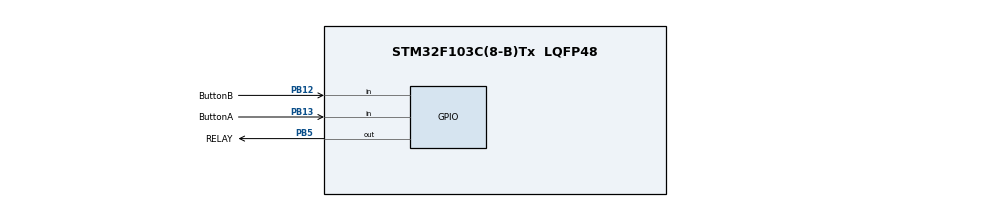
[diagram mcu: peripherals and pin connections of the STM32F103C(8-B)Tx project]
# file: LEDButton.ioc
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Mcu.Family=STM32F1
Mcu.Name=STM32F103C(8-B)Tx
Mcu.Package=LQFP48
NVIC.PriorityGroup=NVIC_PRIORITYGROUP_4
PB12.GPIO_Label=ButtonB
PB12.GPIO_PuPd=GPIO_NOPULL
PB12.Signal=GPIO_Input
PB13.GPIO_Label=ButtonA
PB13.GPIO_PuPd=GPIO_PULLUP
PB13.Signal=GPIO_Input
PB5.GPIO_Label=RELAY
PB5.GPIO_ModeDefaultOutputPP=GPIO_MODE_OUTPUT_PP
PB5.GPIO_PuPd=GPIO_NOPULL
PB5.Signal=GPIO_Output
ProjectManager.HeapSize=0x200
ProjectManager.StackSize=0x400
ProjectManager.TargetToolchain=STM32CubeIDE
RCC.APB1Freq_Value=8000000
RCC.APB2Freq_Value=8000000
board=custom

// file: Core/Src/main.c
/* USER CODE BEGIN Header */
/**
 ******************************************************************************
 * @file           : main.c
 * @brief          : Main program body
 ******************************************************************************
 * @attention
 *
 * Copyright (c) 2025 STMicroelectronics.
 * All rights reserved.
 *
 * This software is licensed under terms that can be found in the LICENSE file
 * in the root directory of this software component.
 * If no LICENSE file comes with this software, it is provided AS-IS.
 *
 ******************************************************************************
 */
/* USER CODE END Header */
#include "main.h"

/* USER CODE BEGIN PV */
int mode = 0;
/* USER CODE END PV */

void SystemClock_Config(void);
static void MX_GPIO_Init(void);
/* USER CODE BEGIN PFP */
GPIO_PinState deBouncing(GPIO_TypeDef *GPIOx, uint16_t GPIO_Pin);

/* USER CODE END PFP */

/* USER CODE BEGIN 0 */
GPIO_PinState deBouncing(GPIO_TypeDef *GPIOx, uint16_t GPIO_Pin) {
	GPIO_PinState bitstatus;
	if (HAL_GPIO_ReadPin(GPIOx, GPIO_Pin) == GPIO_PIN_SET) {
		int count = 0;
		for (int i = 0; i < 100; i++) {
			if (HAL_GPIO_ReadPin(GPIOx, GPIO_Pin) == GPIO_PIN_SET)
				count++;
		}
		if (count >= 90) {
			return GPIO_PIN_SET;
		} else {
			return GPIO_PIN_RESET;
		}
	} else {
		int count = 0;
		for (int i = 0; i < 100; i++) {
			if (HAL_GPIO_ReadPin(GPIOx, GPIO_Pin) == GPIO_PIN_RESET)
				count++;
		}
		if (count >= 90) {
			return GPIO_PIN_RESET;
		} else {
			return GPIO_PIN_SET;
		}
	}
}
/* USER CODE END 0 */

int main(void) {

	/* MCU Configuration--------------------------------------------------------*/

	/* Reset of all peripherals, Initializes the Flash interface and the Systick. */
	HAL_Init();

	/* Configure the system clock */
	SystemClock_Config();

	/* Initialize all configured peripherals */
	MX_GPIO_Init();

	/* Infinite loop */
	/* USER CODE BEGIN WHILE */
	while (1) {
		if (mode == 0) {
			if (deBouncing(ButtonA_GPIO_Port, ButtonA_Pin) == GPIO_PIN_RESET) {
				HAL_GPIO_TogglePin(RELAY_GPIO_Port, RELAY_Pin);
				while (deBouncing(ButtonA_GPIO_Port, ButtonA_Pin)
						== GPIO_PIN_RESET)
					;
			} else {

			}
			if (deBouncing(ButtonB_GPIO_Port, ButtonB_Pin) == GPIO_PIN_RESET) {
				mode = 1;
				while (deBouncing(ButtonB_GPIO_Port, ButtonB_Pin)
						== GPIO_PIN_RESET)
					;
			}
		} else if (mode == 1) {
			if (deBouncing(ButtonA_GPIO_Port, ButtonA_Pin) == GPIO_PIN_RESET) {
				HAL_GPIO_WritePin(RELAY_GPIO_Port, RELAY_Pin, GPIO_PIN_SET);

			} else {
				HAL_GPIO_WritePin(RELAY_GPIO_Port, RELAY_Pin, GPIO_PIN_RESET);
			}
			if (deBouncing(ButtonB_GPIO_Port, ButtonB_Pin) == GPIO_PIN_RESET) {
				mode = 0;
				while (deBouncing(ButtonB_GPIO_Port, ButtonB_Pin)
						== GPIO_PIN_RESET)
					;
			}
		}
		/* USER CODE END WHILE */

	}
}

void SystemClock_Config(void) {
	RCC_OscInitTypeDef RCC_OscInitStruct = { 0 };
	RCC_ClkInitTypeDef RCC_ClkInitStruct = { 0 };

	/** Initializes the RCC Oscillators according to the specified parameters
	 * in the RCC_OscInitTypeDef structure.
	 */
	RCC_OscInitStruct.OscillatorType = RCC_OSCILLATORTYPE_HSI;
	RCC_OscInitStruct.HSIState = RCC_HSI_ON;
	RCC_OscInitStruct.HSICalibrationValue = RCC_HSICALIBRATION_DEFAULT;
	RCC_OscInitStruct.PLL.PLLState = RCC_PLL_NONE;
	if (HAL_RCC_OscConfig(&RCC_OscInitStruct) != HAL_OK) {
		Error_Handler();
	}

	/** Initializes the CPU, AHB and APB buses clocks
	 */
	RCC_ClkInitStruct.ClockType = RCC_CLOCKTYPE_HCLK | RCC_CLOCKTYPE_SYSCLK
			| RCC_CLOCKTYPE_PCLK1 | RCC_CLOCKTYPE_PCLK2;
	RCC_ClkInitStruct.SYSCLKSource = RCC_SYSCLKSOURCE_HSI;
	RCC_ClkInitStruct.AHBCLKDivider = RCC_SYSCLK_DIV1;
	RCC_ClkInitStruct.APB1CLKDivider = RCC_HCLK_DIV1;
	RCC_ClkInitStruct.APB2CLKDivider = RCC_HCLK_DIV1;

	if (HAL_RCC_ClockConfig(&RCC_ClkInitStruct, FLASH_LATENCY_0) != HAL_OK) {
		Error_Handler();
	}
}

static void MX_GPIO_Init(void) {
	GPIO_InitTypeDef GPIO_InitStruct = { 0 };

	/* GPIO Ports Clock Enable */
	__HAL_RCC_GPIOB_CLK_ENABLE();

	/*Configure GPIO pin Output Level */
	HAL_GPIO_WritePin(RELAY_GPIO_Port, RELAY_Pin, GPIO_PIN_RESET);

	/*Configure GPIO pin : ButtonB_Pin */
	GPIO_InitStruct.Pin = ButtonB_Pin;
	GPIO_InitStruct.Mode = GPIO_MODE_INPUT;
	GPIO_InitStruct.Pull = GPIO_NOPULL;
	HAL_GPIO_Init(ButtonB_GPIO_Port, &GPIO_InitStruct);

	/*Configure GPIO pin : ButtonA_Pin */
	GPIO_InitStruct.Pin = ButtonA_Pin;
	GPIO_InitStruct.Mode = GPIO_MODE_INPUT;
	GPIO_InitStruct.Pull = GPIO_PULLUP;
	HAL_GPIO_Init(ButtonA_GPIO_Port, &GPIO_InitStruct);

	/*Configure GPIO pin : RELAY_Pin */
	GPIO_InitStruct.Pin = RELAY_Pin;
	GPIO_InitStruct.Mode = GPIO_MODE_OUTPUT_PP;
	GPIO_InitStruct.Pull = GPIO_NOPULL;
	GPIO_InitStruct.Speed = GPIO_SPEED_FREQ_LOW;
	HAL_GPIO_Init(RELAY_GPIO_Port, &GPIO_InitStruct);

}

void Error_Handler(void) {
	__disable_irq();
	while (1) {
	}
}
